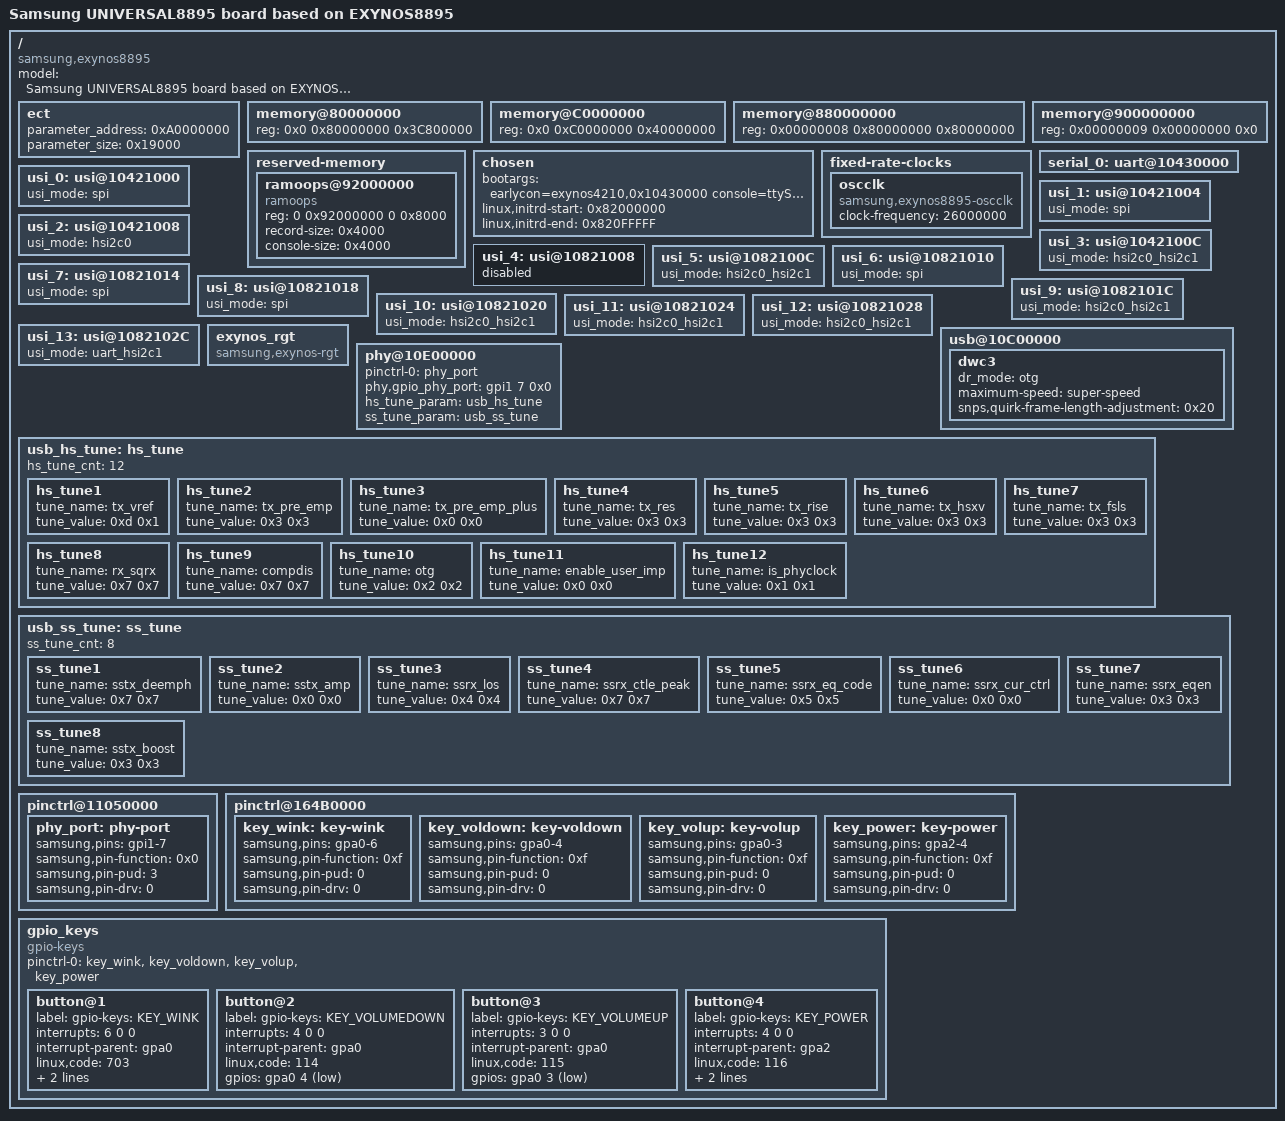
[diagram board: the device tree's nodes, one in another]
/*
 * SAMSUNG EXYNOS8895 board device tree source
 *
 * Copyright (c) 2016 Samsung Electronics Co., Ltd.
 *		http://www.samsung.com
 *
 * This program is free software; you can redistribute it and/or modify
 * it under the terms of the GNU General Public License version 2 as
 * published by the Free Software Foundation.
*/

#include "exynos8895.dtsi"

/ {
	model = "Samsung UNIVERSAL8895 board based on EXYNOS8895";
	compatible = "samsung,exynos8895", "samsung,UNIVERSAL8895";

	ect {
		parameter_address = <0xA0000000>;
		parameter_size = <0x19000>;
	};

	memory@80000000 {
		device_type = "memory";
		reg = <0x0 0x80000000 0x3C800000>;
	};

	memory@C0000000 {
		device_type = "memory";
		reg = <0x0 0xC0000000 0x40000000>;
	};

	memory@880000000 {
		device_type = "memory";
		reg = <0x00000008 0x80000000 0x80000000>;
	};

	memory@900000000 {
		device_type = "memory";
		reg = <0x00000009 0x00000000 0x0>;
	};

	reserved-memory {
		#address-cells = <2>;
		#size-cells = <2>;
		ranges;

		ramoops@92000000 {
			compatible = "ramoops";
			reg = <0 0x92000000 0 0x8000>;
			record-size = <0x4000>;
			console-size = <0x4000>;
		};
	};

	chosen {
		bootargs = "earlycon=exynos4210,0x10430000 console=ttySAC0,115200n8 root=/dev/ram0 clk_ignore_unused ess_setup=0x86000000 androidboot.hardware=samsungexynos8895";
		linux,initrd-start = <0x82000000>;
		linux,initrd-end = <0x820FFFFF>;
	};

	fixed-rate-clocks {
		oscclk {
			compatible = "samsung,exynos8895-oscclk";
			clock-frequency = <26000000>;
		};
	};

	serial_0: uart@10430000 {
		status = "okay";
	};

	/* USI MODE SETTINGS

	   usi_mode = "hsi2c0" or "hsi2c1" or "spi" or "uart"
			or "hsi2c0_hsi2c1" or "uart_hsi2c1"
	 */
	usi_0: usi@10421000 {
		usi_mode = "spi";
		status = "okay";
	};

	usi_1: usi@10421004 {
		usi_mode = "spi";
		status = "okay";
	};

	usi_2: usi@10421008 {
		usi_mode = "hsi2c0";
		status = "okay";
	};

	usi_3: usi@1042100C {
		usi_mode = "hsi2c0_hsi2c1";
		status = "okay";
	};

	usi_4: usi@10821008 {
		status = "disabled";
	};

	usi_5: usi@1082100C {
		usi_mode = "hsi2c0_hsi2c1";
		status = "okay";
	};

	usi_6: usi@10821010 {
		usi_mode = "spi";
		status = "okay";
	};

	usi_7: usi@10821014 {
		usi_mode = "spi";
		status = "okay";
	};

	usi_8: usi@10821018 {
		usi_mode = "spi";
		status = "okay";
	};

	usi_9: usi@1082101C {
		usi_mode = "hsi2c0_hsi2c1";
		status = "okay";
	};

	usi_10: usi@10821020 {
		usi_mode = "hsi2c0_hsi2c1";
		status = "okay";
	};

	usi_11: usi@10821024 {
		usi_mode = "hsi2c0_hsi2c1";
		status = "okay";
	};

	usi_12: usi@10821028 {
		usi_mode = "hsi2c0_hsi2c1";
		status = "okay";
	};

	usi_13: usi@1082102C {
		usi_mode = "uart_hsi2c1";
		status = "okay";
	};

	exynos_rgt {
		compatible = "samsung,exynos-rgt";
	};

	usb@10C00000 {
		status = "okay";
		dwc3 {
			dr_mode = "otg";
			maximum-speed = "super-speed";
			snps,quirk-frame-length-adjustment = <0x20>;
		};
	};

	phy@10E00000 {
		status = "okay";
		pinctrl-names = "default";
		pinctrl-0 = <&phy_port>;
		phy,gpio_phy_port = <&gpi1 7 0x0>;

		hs_tune_param = <&usb_hs_tune>;
		ss_tune_param = <&usb_ss_tune>;
	};

	usb_hs_tune:hs_tune {
		hs_tune_cnt = <12>;

		/* value = <device host> */
		hs_tune1 {
			tune_name = "tx_vref";
			tune_value = <0xd 0x1>;
		};

		hs_tune2 {
			tune_name = "tx_pre_emp";
			tune_value = <0x3 0x3>;
		};

		hs_tune3 {
			tune_name = "tx_pre_emp_plus";
			tune_value = <0x0 0x0>;
		};

		hs_tune4 {
			tune_name = "tx_res";
			tune_value = <0x3 0x3>;
		};

		hs_tune5 {
			tune_name = "tx_rise";
			tune_value = <0x3 0x3>;
		};

		hs_tune6 {
			tune_name = "tx_hsxv";
			tune_value = <0x3 0x3>;
		};

		hs_tune7 {
			tune_name = "tx_fsls";
			tune_value = <0x3 0x3>;
		};

		hs_tune8 {
			tune_name = "rx_sqrx";
			tune_value = <0x7 0x7>;
		};

		hs_tune9 {
			tune_name = "compdis";
			tune_value = <0x7 0x7>;
		};

		hs_tune10 {
			tune_name = "otg";
			tune_value = <0x2 0x2>;
		};

		hs_tune11 {
		/* true : 1, false: 0 */
		/* <enable_user_imp user_imp_value> */
			tune_name = "enable_user_imp";
			tune_value = <0x0 0x0>;
		};

		hs_tune12 {
		/* PHY clk : 1 , FREE clk : 0 */
			tune_name = "is_phyclock";
			tune_value = <0x1 0x1>;
		};
	};

	usb_ss_tune:ss_tune {
		ss_tune_cnt = <8>;

		ss_tune1 {
			tune_name = "sstx_deemph";
			tune_value = <0x7 0x7>;
		};

		ss_tune2 {
			tune_name = "sstx_amp";
			tune_value = <0x0 0x0>;
		};

		ss_tune3 {
			tune_name = "ssrx_los";
			tune_value = <0x4 0x4>;
		};

		ss_tune4 {
			tune_name = "ssrx_ctle_peak";
			tune_value = <0x7 0x7>;
		};

		ss_tune5 {
			tune_name = "ssrx_eq_code";
			tune_value = <0x5 0x5>;
		};

		ss_tune6 {
			tune_name = "ssrx_cur_ctrl";
			tune_value = <0x0 0x0>;
		};

		ss_tune7 {
			tune_name = "ssrx_eqen";
			tune_value = <0x3 0x3>;
		};

		ss_tune8 {
			tune_name = "sstx_boost";
			tune_value = <0x3 0x3>;
		};
	};

	pinctrl@11050000 {
		phy_port: phy-port {
			samsung,pins = "gpi1-7";
			samsung,pin-function = <0x0>;
			samsung,pin-pud = <3>;
			samsung,pin-drv = <0>;
		};
	};

	pinctrl@164B0000 {
		key_wink: key-wink {
			samsung,pins = "gpa0-6";
			samsung,pin-function = <0xf>;
			samsung,pin-pud = <0>;
			samsung,pin-drv = <0>;
		};

		key_voldown: key-voldown {
			samsung,pins = "gpa0-4";
			samsung,pin-function = <0xf>;
			samsung,pin-pud = <0>;
			samsung,pin-drv = <0>;
		};

		key_volup: key-volup {
			samsung,pins = "gpa0-3";
			samsung,pin-function = <0xf>;
			samsung,pin-pud = <0>;
			samsung,pin-drv = <0>;
		};
		key_power: key-power {
			samsung,pins = "gpa2-4";
			samsung,pin-function = <0xf>;
			samsung,pin-pud = <0>;
			samsung,pin-drv = <0>;
		};
	};

	gpio_keys {
		status = "okay";
		compatible = "gpio-keys";
		#address-cells = <1>;
		#size-cells = <0>;
		pinctrl-names = "default";
		pinctrl-0 = <&key_wink &key_voldown &key_volup &key_power>;
		button@1 {
			label = "gpio-keys: KEY_WINK";
			interrupts = <6 0 0>;
			interrupt-parent = <&gpa0>;
			linux,code = <703>;
			gpios = <&gpa0 6 0xf>;
			gpio-key,wakeup = <1>;
		};
		button@2 {
			label = "gpio-keys: KEY_VOLUMEDOWN";
			interrupts = <4 0 0>;
			interrupt-parent = <&gpa0>;
			linux,code = <114>;
			gpios = <&gpa0 4 0xf>;
		};
		button@3 {
			label = "gpio-keys: KEY_VOLUMEUP";
			interrupts = <3 0 0>;
			interrupt-parent = <&gpa0>;
			linux,code = <115>;
			gpios = <&gpa0 3 0xf>;
		};
		button@4 {
			label = "gpio-keys: KEY_POWER";
			interrupts = <4 0 0>;
			interrupt-parent = <&gpa2>;
			linux,code = <116>;
			gpios = <&gpa2 4 0xf>;
			gpio-key,wakeup = <1>;
		};
	};
};
